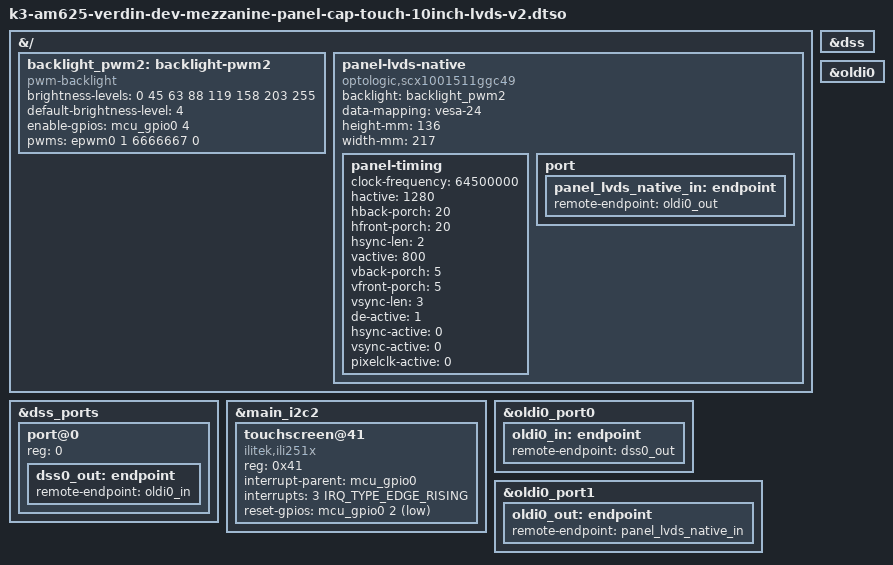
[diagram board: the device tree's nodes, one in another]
// SPDX-License-Identifier: GPL-2.0-or-later OR MIT
/*
 * Copyright (c) Toradex
 *
 * Toradex Capacitive Touch Display 10.1" LVDS V2 on the Verdin AM62 Mezzanine
 * LVDS interface (J10), used with the Verdin Development Board.
 *
 * https://developer.toradex.com/hardware/accessories/displays/capacitive-touch-display-101inch-lvds
 * https://www.toradex.com/accessories/capacitive-touch-display-10.1-inch-lvds
 */

/dts-v1/;
/plugin/;

#include <dt-bindings/gpio/gpio.h>
#include <dt-bindings/interrupt-controller/irq.h>
#include <dt-bindings/pwm/pwm.h>

&{/} {
	backlight_pwm2: backlight-pwm2 {
		compatible = "pwm-backlight";
		brightness-levels = <0 45 63 88 119 158 203 255>;
		default-brightness-level = <4>;
		/* Verdin GPIO_4 (SODIMM 212) - LVDS_BKL_EN */
		enable-gpios = <&mcu_gpio0 4 GPIO_ACTIVE_HIGH>;
		/* Verdin PWM_2 (SODIMM 16) - LVDS_PWM */
		pwms = <&epwm0 1 6666667 0>;
	};

	panel-lvds-native {
		compatible = "optologic,scx1001511ggc49", "panel-lvds";
		backlight = <&backlight_pwm2>;
		data-mapping = "vesa-24";
		height-mm = <136>;
		width-mm = <217>;

		panel-timing {
			clock-frequency = <64500000>;
			hactive = <1280>;
			hback-porch = <20>;
			hfront-porch = <20>;
			hsync-len = <2>;
			vactive = <800>;
			vback-porch = <5>;
			vfront-porch = <5>;
			vsync-len = <3>;
			de-active = <1>;
			hsync-active = <0>;
			vsync-active = <0>;
			pixelclk-active = <0>;
		};

		port {
			panel_lvds_native_in: endpoint {
				remote-endpoint = <&oldi0_out>;
			};
		};
	};
};

&dss {
	status = "okay";
};

&dss_ports {
	#address-cells = <1>;
	#size-cells = <0>;

	/* DSS VP1: internal DPI output to OLDIx */
	port@0 {
		reg = <0>;

		dss0_out: endpoint {
			remote-endpoint = <&oldi0_in>;
		};
	};
};

/* Verdin I2C_2_DSI */
&main_i2c2 {
	#address-cells = <1>;
	#size-cells = <0>;

	touchscreen@41 {
		compatible = "ilitek,ili251x";
		reg = <0x41>;
		/* Verdin GPIO_3 (SODIMM 210) - LVDS_TOUCH_INT# */
		interrupt-parent = <&mcu_gpio0>;
		interrupts = <3 IRQ_TYPE_EDGE_RISING>;
		/* Verdin GPIO_2 (SODIMM 208) - LVDS_TOUCH_RST# */
		reset-gpios = <&mcu_gpio0 2 GPIO_ACTIVE_LOW>;
	};
};

&oldi0 {
	status = "okay";
};

&oldi0_port0 {
	oldi0_in: endpoint {
		remote-endpoint = <&dss0_out>;
	};
};

&oldi0_port1 {
	oldi0_out: endpoint {
		remote-endpoint = <&panel_lvds_native_in>;
	};
};
